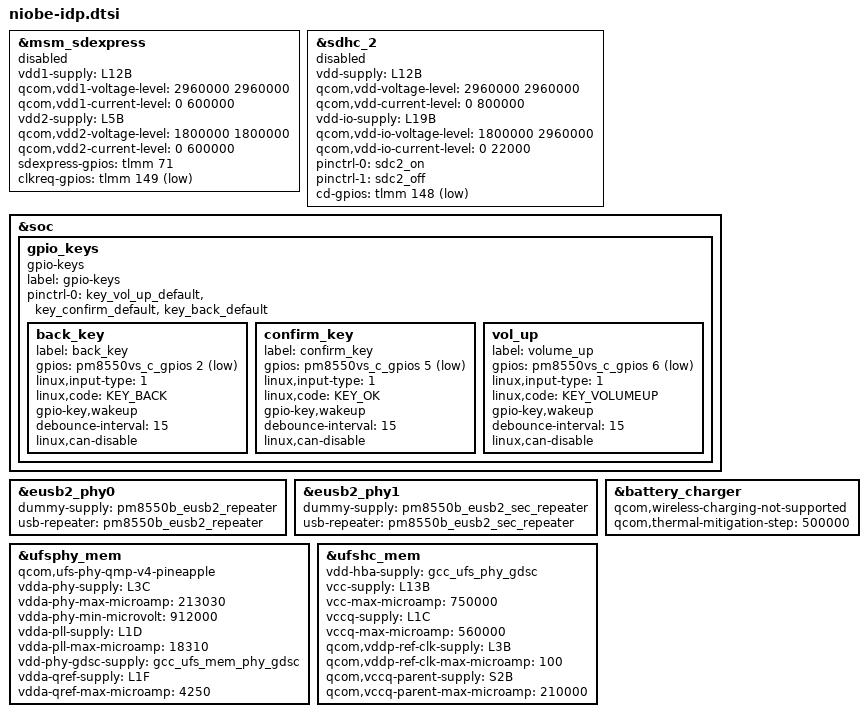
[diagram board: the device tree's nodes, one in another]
#include <dt-bindings/gpio/gpio.h>
#include <dt-bindings/input/input.h>

#include "niobe-pmic-overlay.dtsi"

&msm_sdexpress {
	vdd1-supply = <&L12B>;
	qcom,vdd1-voltage-level = <2960000 2960000>;
	qcom,vdd1-current-level = <0 600000>;

	vdd2-supply = <&L5B>;
	qcom,vdd2-voltage-level = <1800000 1800000>;
	qcom,vdd2-current-level = <0 600000>;

	sdexpress-gpios = <&tlmm 71 0>;
	clkreq-gpios = <&tlmm 149 GPIO_ACTIVE_LOW>;

	status = "disabled";
};

&sdhc_2 {
	status = "disabled";

	vdd-supply = <&L12B>;
	qcom,vdd-voltage-level = <2960000 2960000>;
	qcom,vdd-current-level = <0 800000>;

	vdd-io-supply = <&L19B>;
	qcom,vdd-io-voltage-level = <1800000 2960000>;
	qcom,vdd-io-current-level = <0 22000>;

	pinctrl-names = "default", "sleep";
	pinctrl-0 = <&sdc2_on>;
	pinctrl-1 = <&sdc2_off>;

	cd-gpios = <&tlmm 148 GPIO_ACTIVE_LOW>;
};

&soc {
	gpio_keys {
		compatible = "gpio-keys";
		label = "gpio-keys";

		pinctrl-names = "default";
		pinctrl-0 = <&key_vol_up_default
			     &key_confirm_default
			     &key_back_default>;

		back_key {
			label = "back_key";
			gpios = <&pm8550vs_c_gpios 2 GPIO_ACTIVE_LOW>;
			linux,input-type = <1>;
			linux,code = <KEY_BACK>;
			gpio-key,wakeup;
			debounce-interval = <15>;
			linux,can-disable;
		};

		confirm_key {
			label = "confirm_key";
			gpios = <&pm8550vs_c_gpios 5 GPIO_ACTIVE_LOW>;
			linux,input-type = <1>;
			linux,code = <KEY_OK>;
			gpio-key,wakeup;
			debounce-interval = <15>;
			linux,can-disable;
		};

		vol_up {
			label = "volume_up";
			gpios = <&pm8550vs_c_gpios 6 GPIO_ACTIVE_LOW>;
			linux,input-type = <1>;
			linux,code = <KEY_VOLUMEUP>;
			gpio-key,wakeup;
			debounce-interval = <15>;
			linux,can-disable;
		};
	};
};

&eusb2_phy0 {
	dummy-supply = <&pm8550b_eusb2_repeater>;
	usb-repeater = <&pm8550b_eusb2_repeater>;
};

&eusb2_phy1 {
	dummy-supply = <&pm8550b_eusb2_sec_repeater>;
	usb-repeater = <&pm8550b_eusb2_sec_repeater>;
};

&battery_charger {
	qcom,wireless-charging-not-supported;
	qcom,thermal-mitigation-step = <500000>;
	#cooling-cells = <2>;
};

&ufsphy_mem {
	compatible = "qcom,ufs-phy-qmp-v4-pineapple";

	/* VDDA_UFS_CORE */
	vdda-phy-supply = <&L3C>;
	vdda-phy-max-microamp = <213030>;
	/*
	 * Platforms supporting Gear 5 && Rate B require a different
	 * voltage supply. Check the Power Grid document.
	 */
	vdda-phy-min-microvolt = <912000>;

	/* VDDA_UFS_0_1P2 */
	vdda-pll-supply = <&L1D>;
	vdda-pll-max-microamp =	<18310>;

	/* Phy GDSC for VDD_MX, always on */
	vdd-phy-gdsc-supply = <&gcc_ufs_mem_phy_gdsc>;

	/* Qref power supply, Refer Qref diagram */
	vdda-qref-supply = <&L1F>;
	vdda-qref-max-microamp = <4250>;

	status = "ok";
};

&ufshc_mem {
	vdd-hba-supply = <&gcc_ufs_phy_gdsc>;

	vcc-supply = <&L13B>;
	vcc-max-microamp = <750000>;

	vccq-supply = <&L1C>;
	vccq-max-microamp = <560000>;

	/* VDD_PX10 is voted for the ufs_reset_n */
	qcom,vddp-ref-clk-supply = <&L3B>;
	qcom,vddp-ref-clk-max-microamp = <100>;

	qcom,vccq-parent-supply = <&S2B>;
	qcom,vccq-parent-max-microamp = <210000>;

	status = "ok";
};
